VERSION "Draft 0.2.2 (SW-0)"

NS_ :

BS_:

BU_: TK SRC

CM_ "OBSOLETE: legacy CAN DBC. Документ перенесён в docs/protocols/obsolete/ и больше не является источником правды. Актуальный протокол обмена с ТК: docs/protocols/PROTOCOL_TK_ETHERCAT.md.";

CM_ "DBC для протокола ТК↔ИСТ. Каноника byte-layout: `docs/protocols/obsolete/PROTOCOL_TK.md` / раздел 1.2 (Spec-lock Draft 0.2.2, SW-0). Endianness: Intel (LE) для всех multi-byte полей, включая SERVICE_REQ/RESP.";

CM_ "Важно: DBC фиксирует раскладку/масштабы, но не выражает все правила валидатора (MUST=0, seq-policy, gating ManualDuty и т.п.). Каноника поведения — в `docs/protocols/obsolete/PROTOCOL_TK.md`.";

VAL_ 48 state 0 "IDLE" 1 "ARMED" 2 "WELD" 3 "FAULT";
VAL_ 16 state 0 "IDLE" 1 "ARMED" 2 "WELD" 3 "FAULT";
VAL_ 112 state 0 "IDLE" 1 "ARMED" 2 "WELD" 3 "FAULT";

VAL_ 112 svc_status 0 "OK" 1 "REJECTED" 2 "NOT_ALLOWED" 3 "INVALID_RANGE" 4 "TIMEOUT_EXIT" 5 "INTERNAL_ERR";

VAL_ 96 svc_op 0 "KEEPALIVE" 1 "ENABLE" 2 "DISABLE" 3 "SET_DUTY";

VAL_ 48 fault_code 0 "NONE" 1 "DRIVER_FAULT" 2 "HW_TRIP" 3 "ADC_SPI_TIMEOUT" 4 "ADC_RANGE" 5 "ADC_STUCK" 6 "COMMS_TIMEOUT_HARD" 7 "COMMS_TIMEOUT_SOFT" 8 "BUS_OFF" 9 "CMD_INVALID" 10 "CTRL_OVERRUN" 11 "OVERTEMP" 12 "INCOMPATIBLE_MODE" 13 "INTERNAL_ERR";
VAL_ 16 fault_code 0 "NONE" 1 "DRIVER_FAULT" 2 "HW_TRIP" 3 "ADC_SPI_TIMEOUT" 4 "ADC_RANGE" 5 "ADC_STUCK" 6 "COMMS_TIMEOUT_HARD" 7 "COMMS_TIMEOUT_SOFT" 8 "BUS_OFF" 9 "CMD_INVALID" 10 "CTRL_OVERRUN" 11 "OVERTEMP" 12 "INCOMPATIBLE_MODE" 13 "INTERNAL_ERR";

VAL_ 32 mode 0 "IDLE" 1 "ARMED" 2 "WELD";
VAL_ 32 enable 0 "DISABLE" 1 "ENABLE";
VAL_ 32 fault_reset 0 "NO" 1 "REQUEST";

BO_ 32 CMD_WELD: 16 TK
 SG_ seq                    : 0|16@1+ (1,0) [0|65535] "" SRC
 SG_ mode                   : 16|8@1+ (1,0) [0|2] "" SRC
 SG_ enable                 : 24|8@1+ (1,0) [0|1] "" SRC
 SG_ I_ref_cmd_mA           : 32|32@1- (1,0) [0|50000000] "mA" SRC
 SG_ max_slew_rate_A_ms     : 64|16@1+ (1,0) [0|50000] "A/ms" SRC
 SG_ fault_reset            : 80|8@1+ (1,0) [0|1] "" SRC
 SG_ flags                  : 88|8@1+ (1,0) [0|0] "" SRC
 SG_ crc                    : 96|8@1+ (1,0) [0|0] "" SRC
 SG_ reserved0              : 104|8@1+ (1,0) [0|0] "" SRC
 SG_ reserved1              : 112|16@1+ (1,0) [0|0] "" SRC

BO_ 48 FB_STATUS: 48 SRC
 SG_ seq_applied            : 0|16@1+ (1,0) [0|65535] "" TK
 SG_ state                  : 16|8@1+ (1,0) [0|3] "" TK
 SG_ reserved0              : 24|8@1+ (1,0) [0|0] "" TK
 SG_ status_word            : 32|16@1+ (1,0) [0|65535] "" TK
 SG_ fault_word             : 48|16@1+ (1,0) [0|65535] "" TK
 SG_ limit_word             : 64|16@1+ (1,0) [0|65535] "" TK
 SG_ fault_code             : 80|16@1+ (1,0) [0|13] "" TK
 SG_ I_ref_used_mA          : 96|32@1- (1,0) [0|50000000] "mA" TK
 SG_ duty_used_permille     : 128|16@1+ (1,0) [0|1000] "permille" TK
 SG_ I_per_mA               : 144|32@1- (1,0) [-50000000|50000000] "mA" TK
 SG_ U_per_0p1V             : 176|16@1+ (0.1,0) [0|6553.5] "V" TK
 SG_ reserved_power         : 192|16@1+ (1,0) [0|0] "" TK
 SG_ cnt_cmd_reject         : 208|16@1+ (1,0) [0|65535] "" TK
 SG_ cnt_seq_gap            : 224|16@1+ (1,0) [0|65535] "" TK
 SG_ cnt_adc_fault          : 240|16@1+ (1,0) [0|65535] "" TK
 SG_ cnt_comms_fault        : 256|16@1+ (1,0) [0|65535] "" TK
 SG_ cnt_ctrl_overrun       : 272|16@1+ (1,0) [0|65535] "" TK
 SG_ cnt_log_overrun        : 288|16@1+ (1,0) [0|65535] "" TK
 SG_ reserved_tail0         : 304|8@1+ (1,0) [0|0] "" TK
 SG_ reserved_tail1         : 312|8@1+ (1,0) [0|0] "" TK
 SG_ reserved_tail2         : 320|8@1+ (1,0) [0|0] "" TK
 SG_ reserved_tail3         : 328|8@1+ (1,0) [0|0] "" TK
 SG_ reserved_tail4         : 336|8@1+ (1,0) [0|0] "" TK
 SG_ reserved_tail5         : 344|8@1+ (1,0) [0|0] "" TK
 SG_ reserved_tail6         : 352|8@1+ (1,0) [0|0] "" TK
 SG_ reserved_tail7         : 360|8@1+ (1,0) [0|0] "" TK
 SG_ reserved_tail8         : 368|8@1+ (1,0) [0|0] "" TK
 SG_ reserved_tail9         : 376|8@1+ (1,0) [0|0] "" TK

BO_ 16 FAULT: 16 SRC
 SG_ seq_applied            : 0|16@1+ (1,0) [0|65535] "" TK
 SG_ state                  : 16|8@1+ (1,0) [0|3] "" TK
 SG_ reserved0              : 24|8@1+ (1,0) [0|0] "" TK
 SG_ fault_word             : 32|16@1+ (1,0) [0|65535] "" TK
 SG_ fault_code             : 48|16@1+ (1,0) [0|13] "" TK
 SG_ fault_time_ms          : 64|32@1+ (1,0) [0|4294967295] "ms" TK
 SG_ fault_context          : 96|32@1+ (1,0) [0|0] "" TK

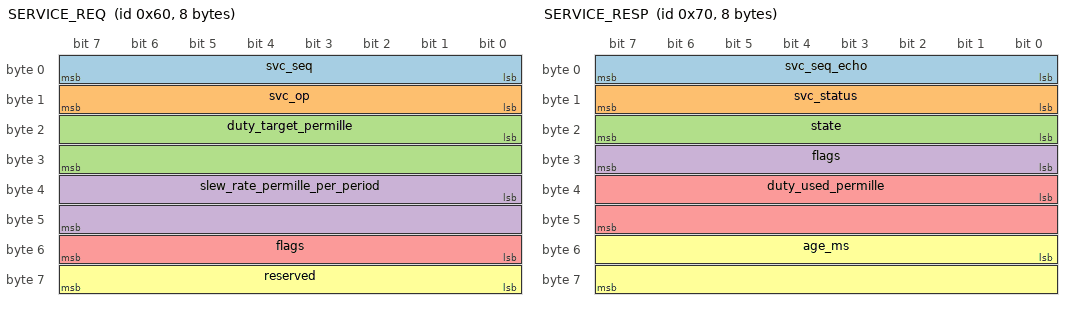
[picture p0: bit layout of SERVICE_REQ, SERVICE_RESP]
BO_ 96 SERVICE_REQ: 8 TK
 SG_ svc_seq                : 0|8@1+ (1,0) [0|255] "" SRC
 SG_ svc_op                 : 8|8@1+ (1,0) [0|3] "" SRC
 SG_ duty_target_permille   : 16|16@1+ (1,0) [0|1000] "permille" SRC
 SG_ slew_rate_permille_per_period : 32|16@1+ (1,0) [0|10] "permille/period" SRC
 SG_ flags                  : 48|8@1+ (1,0) [0|0] "" SRC
 SG_ reserved               : 56|8@1+ (1,0) [0|0] "" SRC

BO_ 112 SERVICE_RESP: 8 SRC
 SG_ svc_seq_echo           : 0|8@1+ (1,0) [0|255] "" TK
 SG_ svc_status             : 8|8@1+ (1,0) [0|5] "" TK
 SG_ state                  : 16|8@1+ (1,0) [0|3] "" TK
 SG_ flags                  : 24|8@1+ (1,0) [0|1] "" TK
 SG_ duty_used_permille     : 32|16@1+ (1,0) [0|1000] "permille" TK
 SG_ age_ms                 : 48|16@1+ (1,0) [0|65535] "ms" TK

CM_ BO_ 32 "CMD_WELD (ТК→Источник), realtime 1 kHz. Каноника валидатора: `docs/protocols/obsolete/PROTOCOL_TK.md` / разделы 1.2 и 3. В Draft 0.2.x flags/crc/reserved* MUST=0.";
CM_ SG_ 32 mode "0=IDLE, 1=ARMED, 2=WELD. Валидация/согласованность с enable — см. PROTOCOL_TK.md / 3.2.";
CM_ SG_ 32 I_ref_cmd_mA "Уставка тока (mA). В Draft 0.2.x валидный диапазон 0..50_000_000 mA; отрицательные значения — ошибка формирования команды (REJECT).";
CM_ SG_ 32 flags "Draft 0.2.x: MUST=0. Ненулевое значение ⇒ REJECT.";
CM_ SG_ 32 crc "Draft 0.2.x: MUST=0 (доп. CRC не используется, CRC обеспечивает CAN FD). Ненулевое значение ⇒ REJECT.";
CM_ SG_ 32 reserved0 "MUST=0. Ненулевое значение ⇒ REJECT.";
CM_ SG_ 32 reserved1 "MUST=0. Ненулевое значение ⇒ REJECT.";

CM_ BO_ 48 "FB_STATUS (Источник→ТК), realtime 1 kHz. Биты status_word/fault_word/limit_word описаны в PROTOCOL_TK.md / 4.1.1.1.";
CM_ SG_ 48 reserved0 "MUST=0 (зарезервировано).";
CM_ SG_ 48 reserved_power "MUST=0 (резерв под совместимость фиксированного DLC).";
CM_ SG_ 48 reserved_tail0 "MUST=0 (reserved_tail[0]).";
CM_ SG_ 48 reserved_tail1 "MUST=0 (reserved_tail[1]).";
CM_ SG_ 48 reserved_tail2 "MUST=0 (reserved_tail[2]).";
CM_ SG_ 48 reserved_tail3 "MUST=0 (reserved_tail[3]).";
CM_ SG_ 48 reserved_tail4 "MUST=0 (reserved_tail[4]).";
CM_ SG_ 48 reserved_tail5 "MUST=0 (reserved_tail[5]).";
CM_ SG_ 48 reserved_tail6 "MUST=0 (reserved_tail[6]).";
CM_ SG_ 48 reserved_tail7 "MUST=0 (reserved_tail[7]).";
CM_ SG_ 48 reserved_tail8 "MUST=0 (reserved_tail[8]).";
CM_ SG_ 48 reserved_tail9 "MUST=0 (reserved_tail[9]).";

CM_ BO_ 16 "FAULT (Источник→ТК), critical. Каноника — PROTOCOL_TK.md / 4.3.";
CM_ SG_ 16 reserved0 "MUST=0.";
CM_ SG_ 16 fault_context "Draft 0.2.2 (SW-0): MUST=0 (резерв под расширенный контекст).";

CM_ BO_ 96 "SERVICE_REQ (ТК→Источник), сервисный домен. Каноника ManualDuty — PROTOCOL_TK.md / 8. Draft 0.2.x flags/reserved MUST=0.";
CM_ SG_ 96 svc_op "0=KEEPALIVE, 1=ENABLE, 2=DISABLE, 3=SET_DUTY. Подробная семантика и gating — PROTOCOL_TK.md / 8.3.1.1 и 8.2.";
CM_ SG_ 96 duty_target_permille "0.1%/LSB. Для ManualDuty применимый диапазон 100..500 (10–50%), иначе INVALID_RANGE/REJECT (см. PROTOCOL_TK.md / 8.3.1.1).";
CM_ SG_ 96 slew_rate_permille_per_period "0=default (2‰/период), иначе допустимо 1..10‰/период; значения вне диапазона ⇒ REJECT (см. PROTOCOL_TK.md / 8.3).";
CM_ SG_ 96 flags "Draft 0.2.x: MUST=0. Ненулевое значение ⇒ REJECT.";
CM_ SG_ 96 reserved "Draft 0.2.x: MUST=0. Ненулевое значение ⇒ REJECT.";

CM_ BO_ 112 "SERVICE_RESP (Источник→ТК), сервисный ответ/телеметрия. flags bit0 = MANUAL_DUTY_ACTIVE, остальные MUST=0 (см. PROTOCOL_TK.md / 8.5).";
